# AM13E23219 register map
Vendor: Texas Instruments; File version: 1.0
CPU: CM33 r0p1, little endian, MPU, FPU, VTOR, 4 interrupt priority bits
Registers are 32-bit, read-write, reset 0x0 unless marked. A register's access mark holds for its fields unless they carry their own. Offsets are from the block's base; [hi:lo] are bit positions; 'fields as' and 'values as' point back to an identical list.

## EAM — EAM module
Base 0x4002C000
0x1000 REVISION ro — IP revision id register
  [0] REVISION
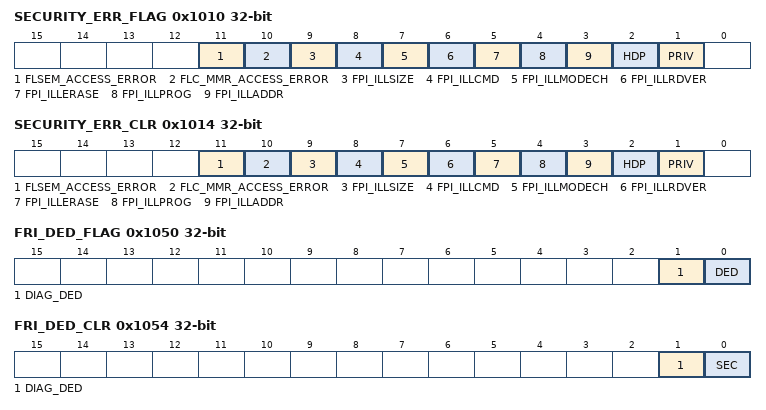
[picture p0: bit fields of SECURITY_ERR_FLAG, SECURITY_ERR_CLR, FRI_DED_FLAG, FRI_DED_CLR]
0x1010 SECURITY_ERR_FLAG ro — Security error flag
  [11] FLSEM_ACCESS_ERROR
  [10] FLC_MMR_ACCESS_ERROR
  [9] FPI_ILLSIZE
  [8] FPI_ILLCMD
  [7] FPI_ILLMODECH
  [6] FPI_ILLRDVER
  [5] FPI_ILLERASE
  [4] FPI_ILLPROG
  [3] FPI_ILLADDR
  [2] HDP — Hide protection error
  [1] PRIV — Privilege error
0x1014 SECURITY_ERR_CLR — Security error clear
  fields as SECURITY_ERR_FLAG
0x1018 SECURITY_ERR_MSTID ro — Security error master id
  [7:0] MSTID — Master ID
0x101C SECURITY_ERR_ADDR access not given — Security error address
0x1030 FRI_SEC_FLAG ro
  [0] SEC — Single error correction error
0x1034 FRI_SEC_CLR — FRI SEC clear
  [0] SEC — Single error correction error
0x1038 FRI_SEC_ADDR access not given — FRI SEC address
0x103C FRI_SEC_MSTID ro — FRI SEC master id
  [7:0] MSTID — Master ID
0x1050 FRI_DED_FLAG ro
  [1] DIAG_DED — diagnostic Double error detect error
  [0] DED — Double error detect error
0x1054 FRI_DED_CLR — FRI DED clear
  [1] DIAG_DED — diagnostic Double error detect error
  [0] SEC — Double error detect error
0x1058 FRI_DED_ADDR access not given — FRI DED address
0x105C FRI_DED_MSTID ro — FRI DED master id
  [7:0] MSTID — Master ID
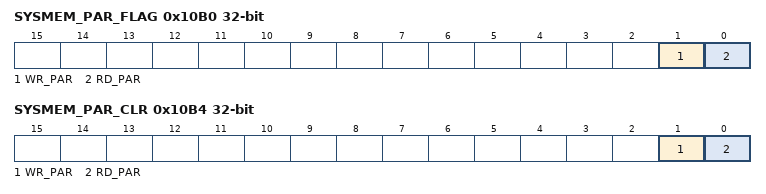
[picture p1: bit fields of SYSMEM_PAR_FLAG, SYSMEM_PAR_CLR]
0x10B0 SYSMEM_PAR_FLAG ro — SYSMEM parity error flag
  [1] WR_PAR — Parity error during write
  [0] RD_PAR — Parity error during read
0x10B4 SYSMEM_PAR_CLR — SYSMEM parity error clear
  [1] WR_PAR — writing '1' will clear SYSMEM_PAR_FLAG[WR_PAR] register.
  [0] RD_PAR — writing '1' will clear SYSMEM_PAR_FLAG[RD_PAR] register.
0x10B8 SYSMEM_PAR_ADDR access not given — SYSMEM parity error address
0x10BC SYSMEM_PAR_MSTID ro — SYSMEM parity error master id
  [7:0] MSTID — Parity error master ID. This field will be cleared along with the corresponding flag clear.
0x10D0 TMUROM_PAR_FLAG ro — TMUROM parity error flag
  [0] PAR — Parity error
0x10D4 TMUROM_PAR_CLR — TMUROM parity error clear
  [0] PAR — writing '1' will clear TMUROM_PAR_FLAG[PAR] register.
0x10D8 TMUROM_PAR_ADDR ro — TMUROM parity error address
  [14:0] ADDRESS — Parity error address. This field will be cleared along with the corresponding flag clear.
0x10DC TMUROM_PAR_TYPE ro — TMUROM parity error type
  [2:0] TYPE — Parity error type. This field will be cleared along with the corresponding flag clear. [0] - Y0i ROM table read has parity error [1] - S1i ROM table read has parity error [2] - S2i ROM table read has parity error
0x10F0 SYSMEM_ACC_FLAG ro — SYSMEM access error flag
  [0] ERR — SYSMEM access error
0x10F4 SYSMEM_ACC_CLR — SYSMEM access error clear
  [0] ERR — writing '1' will clear SYSMEM_ACC_FLAG[ERR] register.
0x10F8 SYSMEM_ACC_ADDR access not given — SYSMEM access error address
0x10FC SYSMEM_ACC_TYPE ro — SYSMEM access error type
  [4:0] TYPE — SRAM access error type. This field will be cleared along with the corresponding flag clear. [4] - CBUS Access Error [3] - SBUS Access Error [2] - Write Error [1] - Read Error [0] - Fetch Error Note: Under the rare condition of both CBUS and SBUS access errors occurring at the same time, bit[4] and bit[3] will be set together to indicate the same, but bits[2:0] (as well as SYSMEM_ACC_ADDR) will convey information only realted to the CBUS access error. Under this condition, the CBUS access error has to be debugged, fixed and rerun before proceeding to debug the SBUS access error.
0x1110 ECATRAM_PAR_FLAG ro — EtherCAT RAM parity error flag
  [0] PAR — Parity error
0x1114 ECATRAM_PAR_CLR — EtherCAT RAM parity error clear
  [0] PAR — writing '1' will clear ECATRAM_PAR_FLAG[PAR] register.
0x1118 ECATRAM_PAR_ADDR access not given — EtherCAT RAM parity error address
